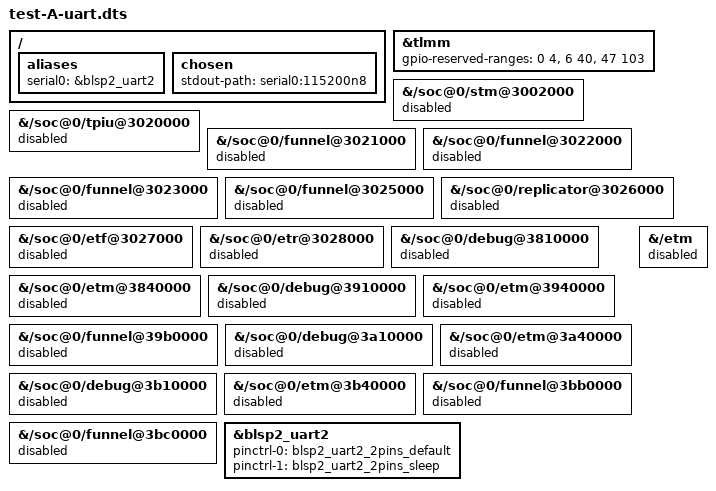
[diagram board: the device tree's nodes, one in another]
#include "../apq8096-samsung-gts3lwifi.dts"

/* Test A-uart: test A, but keep GPIO 4/5 for the debug UART console */
&tlmm {
	/* Test: keep Linux away from every TLMM GPIO except LCD_LDO_EN (46) */
	gpio-reserved-ranges = <0 4>, <6 40>, <47 103>;
};

&{/soc@0/stm@3002000} { status = "disabled"; };
&{/soc@0/tpiu@3020000} { status = "disabled"; };
&{/soc@0/funnel@3021000} { status = "disabled"; };
&{/soc@0/funnel@3022000} { status = "disabled"; };
&{/soc@0/funnel@3023000} { status = "disabled"; };
&{/soc@0/funnel@3025000} { status = "disabled"; };
&{/soc@0/replicator@3026000} { status = "disabled"; };
&{/soc@0/etf@3027000} { status = "disabled"; };
&{/soc@0/etr@3028000} { status = "disabled"; };
&{/soc@0/debug@3810000} { status = "disabled"; };
&{/soc@0/etm@3840000} { status = "disabled"; };
&{/soc@0/debug@3910000} { status = "disabled"; };
&{/soc@0/etm@3940000} { status = "disabled"; };
&{/soc@0/funnel@39b0000} { status = "disabled"; };
&{/soc@0/debug@3a10000} { status = "disabled"; };
&{/soc@0/etm@3a40000} { status = "disabled"; };
&{/soc@0/debug@3b10000} { status = "disabled"; };
&{/soc@0/etm@3b40000} { status = "disabled"; };
&{/soc@0/funnel@3bb0000} { status = "disabled"; };
&{/soc@0/funnel@3bc0000} { status = "disabled"; };
&{/etm} { status = "disabled"; };

/ {
	aliases {
		serial0 = &blsp2_uart2;
	};

	chosen {
		stdout-path = "serial0:115200n8";
	};
};

/* AP debug UART: TX = GPIO 4, RX = GPIO 5, 1.8 V, 115200 8N1 */
&blsp2_uart2 {
	pinctrl-names = "default", "sleep";
	pinctrl-0 = <&blsp2_uart2_2pins_default>;
	pinctrl-1 = <&blsp2_uart2_2pins_sleep>;
	status = "okay";
};
